# LPC111x/LPC11Cxx/LPC11xxL/LPC11xxXL register map
File version: 6
CPU: CM0 r0p0, little endian, no MPU, no FPU, 2 interrupt priority bits
Registers are 32-bit, read-write, reset 0x0 unless marked. A register's access mark holds for its fields unless they carry their own. Offsets are from the block's base; [hi:lo] are bit positions; 'fields as' and 'values as' point back to an identical list.

## IOCON — I/O Configuration Block
Base 0x40044000
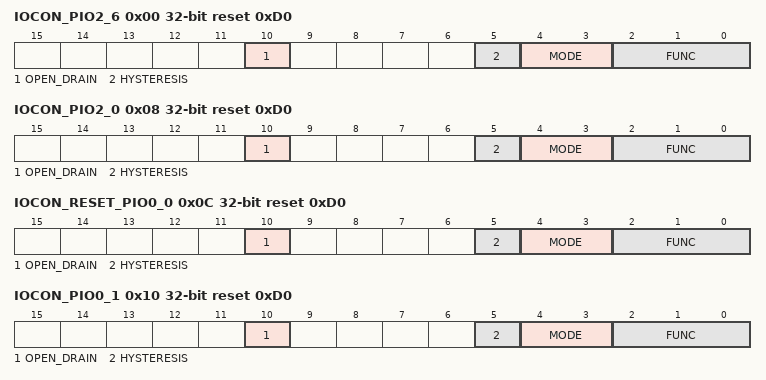
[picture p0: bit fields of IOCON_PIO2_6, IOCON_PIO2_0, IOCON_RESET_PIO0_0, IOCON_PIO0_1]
0x00 IOCON_PIO2_6 reset 0xD0 — I/O configuration for pin PIO2_6/ CT32B0_MAT1
  [10] OPEN_DRAIN — Selects pseudo open-drain mode.
    0=GPIO_OUTPUT (Standard GPIO output); 1=OPEN_DRAIN_OUTPUT
  [5] HYSTERESIS
    0=DISABLE; 1=ENABLE
  [4:3] MODE — Pin function mode (on-chip pull-up/pull-down resistor control).
    0=INACTIVE_NO_PULL_DO (Inactive (no pull-down/pull-up resistor enabled)); 1=PULL_DOWN_RESISTOR_E (Pull-down resistor enabled); 2=PULL_UP_RESISTOR_ENA (Pull-up resistor enabled); 3=REPEATER_MODE_
  [2:0] FUNC — Configure pin function.
    0=PIO2_6 (Pin function PIO2_6); 1=CT32B0_MAT1 (Pin function CT32B0_MAT1)
0x08 IOCON_PIO2_0 reset 0xD0 — I/O configuration for pin PIO2_0/DTR/SSEL1
  [10] OPEN_DRAIN — Selects pseudo open-drain mode.
    0=GPIO_OUTPUT (Standard GPIO output); 1=OPEN_DRAIN_OUTPUT
  [5] HYSTERESIS
    0=DISABLE; 1=ENABLE
  [4:3] MODE — Pin function mode (on-chip pull-up/pull-down resistor control).
    values as IOCON_PIO2_6.MODE
  [2:0] FUNC — Configure pin function.
    0=PIO2_0 (Pin function PIO2_0); 1=DTR (Pin function DTR); 2=SSEL1 (Pin function SSEL1)
0x0C IOCON_RESET_PIO0_0 reset 0xD0 — I/O configuration for pin RESET/PIO0_0
  [10] OPEN_DRAIN — Selects pseudo open-drain mode.
    0=GPIO_OUTPUT (Standard GPIO output); 1=OPEN_DRAIN_OUTPUT
  [5] HYSTERESIS
    0=DISABLE; 1=ENABLE
  [4:3] MODE — Pin function mode (on-chip pull-up/pull-down resistor control).
    values as IOCON_PIO2_6.MODE
  [2:0] FUNC — Configure pin function.
    0=RESET (Pin function RESET); 1=PIO0_0 (Pin function PIO0_0)
0x10 IOCON_PIO0_1 reset 0xD0 — I/O configuration for pin PIO0_1/CLKOUT/CT32B0_MAT2
  [10] OPEN_DRAIN — Selects pseudo open-drain mode.
    0=GPIO_OUTPUT (Standard GPIO output); 1=OPEN_DRAIN_OUTPUT
  [5] HYSTERESIS
    0=DISABLE; 1=ENABLE
  [4:3] MODE — Pin function mode (on-chip pull-up/pull-down resistor control).
    values as IOCON_PIO2_6.MODE
  [2:0] FUNC — Configure pin function.
    0=PIO0_1 (Pin function PIO0_1); 1=CLKOUT (Pin function CLKOUT); 2=CT32B0_MAT2 (Pin function CT32B0_MAT2)
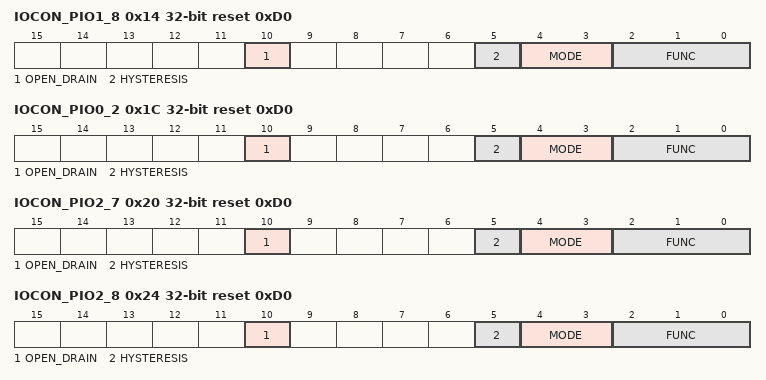
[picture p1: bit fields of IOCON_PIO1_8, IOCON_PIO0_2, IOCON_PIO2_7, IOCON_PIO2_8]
0x14 IOCON_PIO1_8 reset 0xD0 — I/O configuration for pin PIO1_8/CT16B1_CAP0
  [10] OPEN_DRAIN — Selects pseudo open-drain mode.
    0=GPIO_OUTPUT (Standard GPIO output); 1=OPEN_DRAIN_OUTPUT
  [5] HYSTERESIS
    0=DISABLE; 1=ENABLE
  [4:3] MODE — Pin function mode (on-chip pull-up/pull-down resistor control).
    values as IOCON_PIO2_6.MODE
  [2:0] FUNC — Configure pin function.
    0=PIO1_8 (Pin function PIO1_8); 1=CT16B1_CAP0 (Pin function CT16B1_CAP0)
0x18 IOCON_SSEL1_LOC — SSEL1 pin location select register
  [1:0] SSEL1LOC — Selects pin location for SSEL1 function.
    0=PIO2_2 (Function SSEL1 is available for pin PIO2_2); 1=PIO2_4 (Function SSEL1 is available for pin PIO2_4)
0x1C IOCON_PIO0_2 reset 0xD0 — I/O configuration for pin PIO0_2/SSEL0/CT16B0_CAP0
  [10] OPEN_DRAIN — Selects pseudo open-drain mode.
    0=GPIO_OUTPUT (Standard GPIO output); 1=OPEN_DRAIN_OUTPUT
  [5] HYSTERESIS
    0=DISABLE; 1=ENABLE
  [4:3] MODE — Pin function mode (on-chip pull-up/pull-down resistor control).
    values as IOCON_PIO2_6.MODE
  [2:0] FUNC — Configure pin function.
    0=PIO0_2 (Pin function PIO0_2); 1=SSEL0 (Pin function SSEL0); 2=CT16B0_CAP0 (Pin function CT16B0_CAP0)
0x20 IOCON_PIO2_7 reset 0xD0 — I/O configuration for pin PIO2_7/ CT32B0_MAT2/RXD
  [10] OPEN_DRAIN — Selects pseudo open-drain mode.
    0=GPIO_OUTPUT (Standard GPIO output); 1=OPEN_DRAIN_OUTPUT
  [5] HYSTERESIS
    0=DISABLE; 1=ENABLE
  [4:3] MODE — Pin function mode (on-chip pull-up/pull-down resistor control).
    values as IOCON_PIO2_6.MODE
  [2:0] FUNC — Configure pin function.
    0=PIO2_7 (Pin function PIO2_7); 1=CT32B0_MAT2 (Pin function CT32B0_MAT2); 2=RXD (Pin function RXD)
0x24 IOCON_PIO2_8 reset 0xD0 — I/O configuration for pin PIO2_8/ CT32B0_MAT3/TXD
  [10] OPEN_DRAIN — Selects pseudo open-drain mode.
    0=GPIO_OUTPUT (Standard GPIO output); 1=OPEN_DRAIN_OUTPUT
  [5] HYSTERESIS
    0=DISABLE; 1=ENABLE
  [4:3] MODE — Pin function mode (on-chip pull-up/pull-down resistor control).
    values as IOCON_PIO2_6.MODE
  [2:0] FUNC — Configure pin function.
    0=PIO2_8 (Pin function PIO2_8); 1=CT32B0_MAT3 (Pin function CT32B0_MAT3); 2=TXD (Pin function TXD)
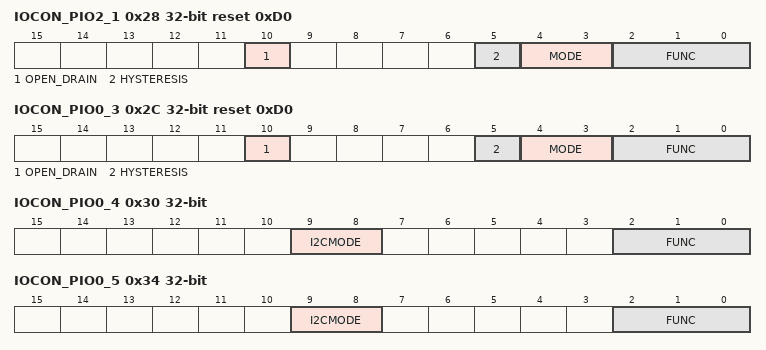
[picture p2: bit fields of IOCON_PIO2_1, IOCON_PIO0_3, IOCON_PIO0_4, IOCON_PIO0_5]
0x28 IOCON_PIO2_1 reset 0xD0 — I/O configuration for pin PIO2_1/DSR/SCK1
  [10] OPEN_DRAIN — Selects pseudo open-drain mode.
    0=GPIO_OUTPUT (Standard GPIO output); 1=OPEN_DRAIN_OUTPUT
  [5] HYSTERESIS
    0=DISABLE; 1=ENABLE
  [4:3] MODE — Pin function mode (on-chip pull-up/pull-down resistor control).
    values as IOCON_PIO2_6.MODE
  [2:0] FUNC — Configure pin function.
    0=PIO2_1 (Pin function PIO2_1); 1=DSR (Pin function DSR); 2=SCK1 (Pin function SCK1)
0x2C IOCON_PIO0_3 reset 0xD0 — I/O configuration for pin PIO0_3
  [10] OPEN_DRAIN — Selects pseudo open-drain mode.
    0=GPIO_OUTPUT (Standard GPIO output); 1=OPEN_DRAIN_OUTPUT
  [5] HYSTERESIS
    0=DISABLE; 1=ENABLE
  [4:3] MODE — Pin function mode (on-chip pull-up/pull-down resistor control).
    values as IOCON_PIO2_6.MODE
  [2:0] FUNC — Configure pin function.
    0=PIO0_3 (Pin function PIO0_3)
0x30 IOCON_PIO0_4 — I/O configuration for pin PIO0_4/SCL
  [9:8] I2CMODE — Selects I2C mode. Select Standard mode (I2CMODE = 00, default) or Standard I/O functionality (I2CMODE = 01) if the pin function is GPIO (FUNC = 000).
    0=STANDARD_MODE_FAST (Standard mode/ Fast-mode I2C); 1=STANDARD_IO_FUNCTION (Standard I/O functionality); 2=FAST_MODE_PLUS_I2C
  [2:0] FUNC — Configure pin function.
    0=PIO0_4 (Pin function PIO0_4 (open-drain pin)); 1=SCL (Pin function SCL (open-drain pin))
0x34 IOCON_PIO0_5 — I/O configuration for pin PIO0_5/SDA
  [9:8] I2CMODE — Selects I2C mode. Select Standard mode (I2CMODE = 00, default) or Standard I/O functionality (I2CMODE = 01) if the pin function is GPIO (FUNC = 000).
    values as IOCON_PIO0_4.I2CMODE
  [2:0] FUNC — Configure pin function.
    0=PIO0_5 (Pin function PIO0_5 (open-drain pin)); 1=SDA (Pin function SDA (open-drain pin))
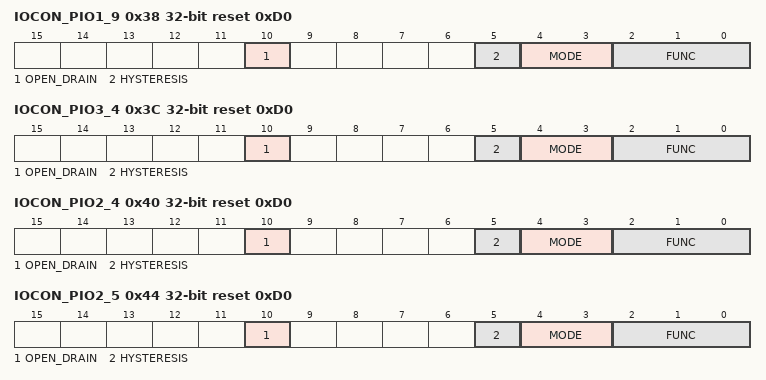
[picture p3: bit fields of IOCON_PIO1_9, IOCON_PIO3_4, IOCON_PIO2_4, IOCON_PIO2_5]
0x38 IOCON_PIO1_9 reset 0xD0 — I/O configuration for pin PIO1_9/CT16B1_MAT0/ MOSI1
  [10] OPEN_DRAIN — Selects pseudo open-drain mode.
    0=GPIO_OUTPUT (Standard GPIO output); 1=OPEN_DRAIN_OUTPUT
  [5] HYSTERESIS
    0=DISABLE; 1=ENABLE
  [4:3] MODE — Pin function mode (on-chip pull-up/pull-down resistor control).
    values as IOCON_PIO2_6.MODE
  [2:0] FUNC — Configure pin function.
    0=PIO1_9 (Pin function PIO1_9); 1=CT16B1_MAT0 (Pin function CT16B1_MAT0); 2=MOSI1 (Pin function MOSI1)
0x3C IOCON_PIO3_4 reset 0xD0 — I/O configuration for pin PIO3_4/ CT16B0_CAP1/RXD
  [10] OPEN_DRAIN — Selects pseudo open-drain mode.
    0=GPIO_OUTPUT (Standard GPIO output); 1=OPEN_DRAIN_OUTPUT
  [5] HYSTERESIS
    0=DISABLE; 1=ENABLE
  [4:3] MODE — Pin function mode (on-chip pull-up/pull-down resistor control).
    values as IOCON_PIO2_6.MODE
  [2:0] FUNC — Configure pin function.
    0=PIO3_4 (Pin function PIO3_4); 1=CT16B0_CAP1 (Pin function CT16B0_CAP1); 2=RXD (Pin function RXD)
0x40 IOCON_PIO2_4 reset 0xD0 — I/O configuration for pin PIO2_4/ CT16B1_MAT1/ SSEL1
  [10] OPEN_DRAIN — Selects pseudo open-drain mode.
    0=GPIO_OUTPUT (Standard GPIO output); 1=OPEN_DRAIN_OUTPUT
  [5] HYSTERESIS
    0=DISABLE; 1=ENABLE
  [4:3] MODE — Pin function mode (on-chip pull-up/pull-down resistor control).
    values as IOCON_PIO2_6.MODE
  [2:0] FUNC — Configure pin function.
    0=PIO2_4 (Pin function PIO2_4); 1=CT16B1_MAT1 (Pin function CT16B1_MAT1); 2=SSEL1 (Pin function SSEL1)
0x44 IOCON_PIO2_5 reset 0xD0 — I/O configuration for pin PIO2_5/ CT32B0_MAT0
  [10] OPEN_DRAIN — Selects pseudo open-drain mode.
    0=GPIO_OUTPUT (Standard GPIO output); 1=OPEN_DRAIN_OUTPUT
  [5] HYSTERESIS
    0=DISABLE; 1=ENABLE
  [4:3] MODE — Pin function mode (on-chip pull-up/pull-down resistor control).
    values as IOCON_PIO2_6.MODE
  [2:0] FUNC — Configure pin function.
    0=PIO2_5 (Pin function PIO2_5); 1=CT32B0_MAT0 (Pin function CT32B0_MAT0)
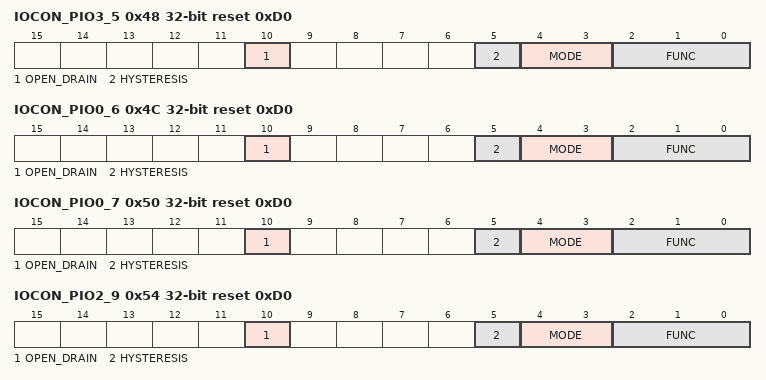
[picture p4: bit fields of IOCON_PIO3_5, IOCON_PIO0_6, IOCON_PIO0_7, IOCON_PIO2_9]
0x48 IOCON_PIO3_5 reset 0xD0 — I/O configuration for pin PIO3_5/ CT16B1_CAP1/TXD
  [10] OPEN_DRAIN — Selects pseudo open-drain mode.
    0=GPIO_OUTPUT (Standard GPIO output); 1=OPEN_DRAIN_OUTPUT
  [5] HYSTERESIS
    0=DISABLE; 1=ENABLE
  [4:3] MODE — Pin function mode (on-chip pull-up/pull-down resistor control).
    values as IOCON_PIO2_6.MODE
  [2:0] FUNC — Configure pin function.
    0=PIO3_5 (Pin function PIO3_5); 1=CT16B1_CAP1 (Pin function CT16B1_CAP1); 2=TXD (Pin function TXD)
0x4C IOCON_PIO0_6 reset 0xD0 — I/O configuration for pin PIO0_6/SCK0
  [10] OPEN_DRAIN — Selects pseudo open-drain mode.
    0=GPIO_OUTPUT (Standard GPIO output); 1=OPEN_DRAIN_OUTPUT
  [5] HYSTERESIS
    0=DISABLE; 1=ENABLE
  [4:3] MODE — Pin function mode (on-chip pull-up/pull-down resistor control).
    values as IOCON_PIO2_6.MODE
  [2:0] FUNC — Configure pin function.
    0=PIO0_6 (Pin function PIO0_6); 2=SCK0 (Pin function SCK0 (available depending on SCK location register))
0x50 IOCON_PIO0_7 reset 0xD0 — I/O configuration for pin PIO0_7/CTS
  [10] OPEN_DRAIN — Selects pseudo open-drain mode.
    0=GPIO_OUTPUT (Standard GPIO output); 1=OPEN_DRAIN_OUTPUT
  [5] HYSTERESIS
    0=DISABLE; 1=ENABLE
  [4:3] MODE — Pin function mode (on-chip pull-up/pull-down resistor control).
    values as IOCON_PIO2_6.MODE
  [2:0] FUNC — Configure pin function.
    0=PIO0_7 (Pin function PIO0_7); 1=CTS (Pin function CTS)
0x54 IOCON_PIO2_9 reset 0xD0 — I/O configuration for pin PIO2_9/ CT32B0_CAP0
  [10] OPEN_DRAIN — Selects pseudo open-drain mode.
    0=GPIO_OUTPUT (Standard GPIO output); 1=OPEN_DRAIN_OUTPUT
  [5] HYSTERESIS
    0=DISABLE; 1=ENABLE
  [4:3] MODE — Pin function mode (on-chip pull-up/pull-down resistor control).
    values as IOCON_PIO2_6.MODE
  [2:0] FUNC — Configure pin function.
    0=PIO2_9 (Pin function PIO2_9); 1=CT32B0_CAP0 (Pin function CT32B0_CAP0)
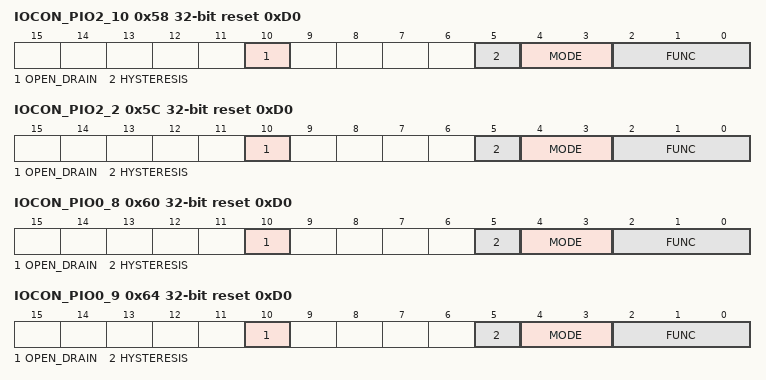
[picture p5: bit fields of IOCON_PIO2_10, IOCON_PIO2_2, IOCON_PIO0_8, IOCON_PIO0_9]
0x58 IOCON_PIO2_10 reset 0xD0 — I/O configuration for pin PIO2_10
  [10] OPEN_DRAIN — Selects pseudo open-drain mode.
    0=GPIO_OUTPUT (Standard GPIO output); 1=OPEN_DRAIN_OUTPUT
  [5] HYSTERESIS
    0=DISABLE; 1=ENABLE
  [4:3] MODE — Pin function mode (on-chip pull-up/pull-down resistor control).
    values as IOCON_PIO2_6.MODE
  [2:0] FUNC — Configure pin function.
    0=PIO2_10 (Pin function PIO2_10)
0x5C IOCON_PIO2_2 reset 0xD0 — I/O configuration for pin PIO2_2/DCD/MISO1
  [10] OPEN_DRAIN — Selects pseudo open-drain mode.
    0=GPIO_OUTPUT (Standard GPIO output); 1=OPEN_DRAIN_OUTPUT
  [5] HYSTERESIS
    0=DISABLE; 1=ENABLE
  [4:3] MODE — Pin function mode (on-chip pull-up/pull-down resistor control).
    values as IOCON_PIO2_6.MODE
  [2:0] FUNC — Configure pin function.
    0=PIO2_2 (Pin function PIO2_2); 1=DCD (Pin function DCD); 2=MISO1 (Pin function MISO1)
0x60 IOCON_PIO0_8 reset 0xD0 — I/O configuration for pin PIO0_8/MISO0/CT16B0_MAT0
  [10] OPEN_DRAIN — Selects pseudo open-drain mode.
    0=GPIO_OUTPUT (Standard GPIO output); 1=OPEN_DRAIN_OUTPUT
  [5] HYSTERESIS
    0=DISABLE; 1=ENABLE
  [4:3] MODE — Pin function mode (on-chip pull-up/pull-down resistor control).
    values as IOCON_PIO2_6.MODE
  [2:0] FUNC — Configure pin function.
    0=PIO0_8 (Pin function PIO0_8); 1=MISO0 (Pin function MISO0); 2=CT16B0_MAT0 (Pin function CT16B0_MAT0)
0x64 IOCON_PIO0_9 reset 0xD0 — I/O configuration for pin PIO0_9/MOSI0/CT16B0_MAT1
  [10] OPEN_DRAIN — Selects pseudo open-drain mode.
    0=GPIO_OUTPUT (Standard GPIO output); 1=OPEN_DRAIN_OUTPUT
  [5] HYSTERESIS
    0=DISABLE; 1=ENABLE
  [4:3] MODE — Pin function mode (on-chip pull-up/pull-down resistor control).
    values as IOCON_PIO2_6.MODE
  [2:0] FUNC — Configure pin function.
    0=PIO0_9 (Pin function PIO0_9); 1=MOSI0 (Pin function MOSI0); 2=CT16B0_MAT1 (Pin function CT16B0_MAT1)
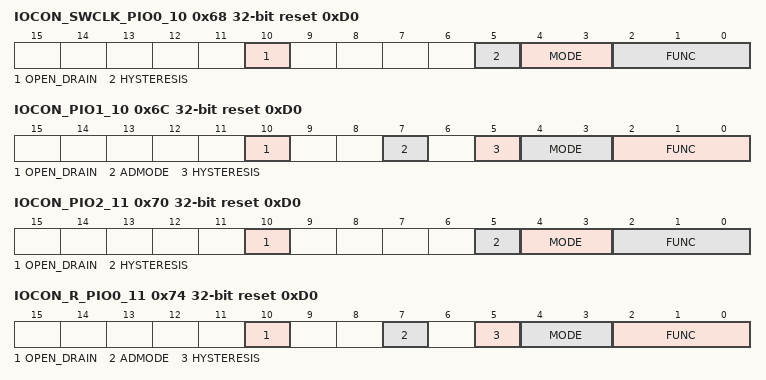
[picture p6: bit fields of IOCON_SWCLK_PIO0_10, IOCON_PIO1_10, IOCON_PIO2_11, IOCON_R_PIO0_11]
0x68 IOCON_SWCLK_PIO0_10 reset 0xD0 — I/O configuration for pin SWCLK/PIO0_10/ SCK0/CT16B0_MAT2
  [10] OPEN_DRAIN — Selects pseudo open-drain mode.
    0=GPIO_OUTPUT (Standard GPIO output); 1=OPEN_DRAIN_OUTPUT
  [5] HYSTERESIS
    0=DISABLE; 1=ENABLE
  [4:3] MODE — Pin function mode (on-chip pull-up/pull-down resistor control).
    values as IOCON_PIO2_6.MODE
  [2:0] FUNC — Configure pin function.
    0=SWCLK (Pin function SWCLK); 1=PIO0_10 (Pin function PIO0_10); 2=SCK0 (Pin function SCK0 (available depending on SCK location register)); 3=CT16B0_MAT2 (Pin function CT16B0_MAT2)
0x6C IOCON_PIO1_10 reset 0xD0 — I/O configuration for pin PIO1_10/AD6/CT16B1_MAT1/ MISO1
  [10] OPEN_DRAIN — Selects pseudo open-drain mode.
    0=GPIO_OUTPUT (Standard GPIO output); 1=OPEN_DRAIN_OUTPUT
  [7] ADMODE — Selects Analog/Digital mode.
    0=ANALOG_INPUT_MODE; 1=DIGITAL_FUNCTIONAL_M (Digital functional mode)
  [5] HYSTERESIS
    0=DISABLE; 1=ENABLE
  [4:3] MODE — Pin function mode (on-chip pull-up/pull-down resistor control).
    values as IOCON_PIO2_6.MODE
  [2:0] FUNC — Configure pin function.
    0=PIO1_10 (Pin function PIO1_10); 1=AD6 (Pin function AD6); 2=CT16B1_MAT1 (Pin function CT16B1_MAT1); 3=MISO1 (Pin function MISO1)
0x70 IOCON_PIO2_11 reset 0xD0 — I/O configuration for pin PIO2_11/SCK0/ CT32B0_CAP1
  [10] OPEN_DRAIN — Selects pseudo open-drain mode.
    0=GPIO_OUTPUT (Standard GPIO output); 1=OPEN_DRAIN_OUTPUT
  [5] HYSTERESIS
    0=DISABLE; 1=ENABLE
  [4:3] MODE — Pin function mode (on-chip pull-up/pull-down resistor control).
    values as IOCON_PIO2_6.MODE
  [2:0] FUNC — Configure pin function.
    0=PIO2_11 (Pin function PIO2_11); 1=SELECT_FUNCTION_SCK0 (Pin function SCK0 (only if pin PIO2_11/SCK0 selected in Table 147)); 2=CT32B0_CAP1 (Pin function CT32B0_CAP1)
0x74 IOCON_R_PIO0_11 reset 0xD0 — I/O configuration for pin R/PIO0_11/AD0/CT32B0_MAT3
  [10] OPEN_DRAIN — Selects pseudo open-drain mode.
    0=GPIO_OUTPUT (Standard GPIO output); 1=OPEN_DRAIN_OUTPUT
  [7] ADMODE — Selects Analog/Digital mode.
    values as IOCON_PIO1_10.ADMODE
  [5] HYSTERESIS
    0=DISABLE; 1=ENABLE
  [4:3] MODE — Pin function mode (on-chip pull-up/pull-down resistor control).
    values as IOCON_PIO2_6.MODE
  [2:0] FUNC — Configure pin function.
    1=PIO0_11 (Pin function PIO0_11); 2=AD0 (Pin function AD0); 3=CT32B0_MAT3 (Pin function CT32B0_MAT3)
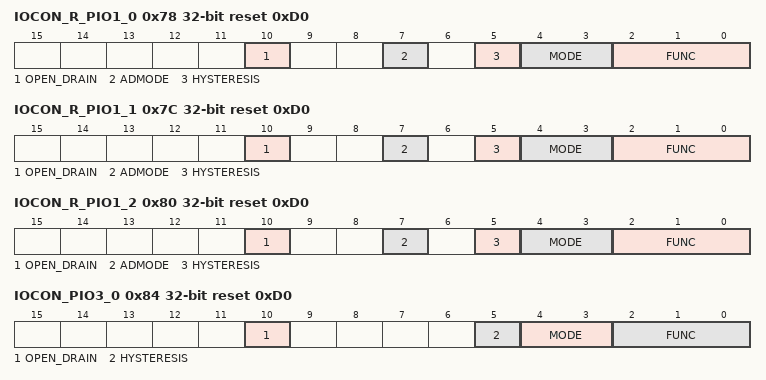
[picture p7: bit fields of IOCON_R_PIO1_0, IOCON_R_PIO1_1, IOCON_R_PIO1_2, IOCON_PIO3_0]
0x78 IOCON_R_PIO1_0 reset 0xD0 — I/O configuration for pin R/PIO1_0/AD1/CT32B1_CAP0
  [10] OPEN_DRAIN — Selects pseudo open-drain mode.
    0=GPIO_OUTPUT (Standard GPIO output); 1=OPEN_DRAIN_OUTPUT
  [7] ADMODE — Selects Analog/Digital mode.
    values as IOCON_PIO1_10.ADMODE
  [5] HYSTERESIS
    0=DISABLE; 1=ENABLE
  [4:3] MODE — Pin function mode (on-chip pull-up/pull-down resistor control).
    values as IOCON_PIO2_6.MODE
  [2:0] FUNC — Configure pin function.
    1=PIO1_0 (Pin function PIO1_0); 2=AD1 (Pin function AD1); 3=CT32B1_CAP0 (Pin function CT32B1_CAP0)
0x7C IOCON_R_PIO1_1 reset 0xD0 — I/O configuration for pin R/PIO1_1/AD2/CT32B1_MAT0
  [10] OPEN_DRAIN — Selects pseudo open-drain mode.
    0=GPIO_OUTPUT (Standard GPIO output); 1=OPEN_DRAIN_OUTPUT
  [7] ADMODE — Selects Analog/Digital mode.
    values as IOCON_PIO1_10.ADMODE
  [5] HYSTERESIS
    0=DISABLE; 1=ENABLE
  [4:3] MODE — Pin function mode (on-chip pull-up/pull-down resistor control).
    values as IOCON_PIO2_6.MODE
  [2:0] FUNC — Configure pin function.
    1=PIO1_1 (Pin function PIO1_1); 2=AD2 (Pin function AD2); 3=CT32B1_MAT0 (Pin function CT32B1_MAT0)
0x80 IOCON_R_PIO1_2 reset 0xD0 — I/O configuration for pin R/PIO1_2/AD3/CT32B1_MAT1
  [10] OPEN_DRAIN — Selects pseudo open-drain mode.
    0=GPIO_OUTPUT (Standard GPIO output); 1=OPEN_DRAIN_OUTPUT
  [7] ADMODE — Selects Analog/Digital mode.
    values as IOCON_PIO1_10.ADMODE
  [5] HYSTERESIS
    0=DISABLE; 1=ENABLE
  [4:3] MODE — Pin function mode (on-chip pull-up/pull-down resistor control).
    values as IOCON_PIO2_6.MODE
  [2:0] FUNC — Configure pin function.
    1=PIO1_2 (Pin function PIO1_2); 2=AD3 (Pin function AD3); 3=CT32B1_MAT1 (Pin function CT32B1_MAT1)
0x84 IOCON_PIO3_0 reset 0xD0 — I/O configuration for pin PIO3_0/DTR/CT16B0_MAT0/TXD
  [10] OPEN_DRAIN — Selects pseudo open-drain mode.
    0=GPIO_OUTPUT (Standard GPIO output); 1=OPEN_DRAIN_OUTPUT
  [5] HYSTERESIS
    0=DISABLE; 1=ENABLE
  [4:3] MODE — Pin function mode (on-chip pull-up/pull-down resistor control).
    values as IOCON_PIO2_6.MODE
  [2:0] FUNC — Configure pin function.
    0=PIO3_0 (Pin function PIO3_0); 1=DTR (Pin function DTR); 2=CT16B0_MAT0 (Pin function CT16B0_MAT0); 3=TXD (Pin function TXD)
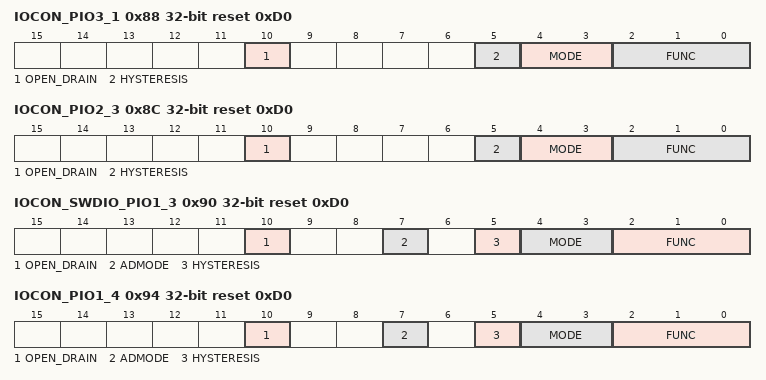
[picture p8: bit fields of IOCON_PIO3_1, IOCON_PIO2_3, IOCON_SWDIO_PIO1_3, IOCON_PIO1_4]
0x88 IOCON_PIO3_1 reset 0xD0 — I/O configuration for pin PIO3_1/DSR/CT16B0_MAT1/RXD
  [10] OPEN_DRAIN — Selects pseudo open-drain mode.
    0=GPIO_OUTPUT (Standard GPIO output); 1=OPEN_DRAIN_OUTPUT
  [5] HYSTERESIS
    0=DISABLE; 1=ENABLE
  [4:3] MODE — Pin function mode (on-chip pull-up/pull-down resistor control).
    values as IOCON_PIO2_6.MODE
  [2:0] FUNC — Configure pin function.
    0=PIO3_1 (Pin function PIO3_1); 1=DSR (Pin function DSR); 2=CT16B0_MAT1 (Pin function CT16B0_MAT1); 3=RXD (Pin function RXD)
0x8C IOCON_PIO2_3 reset 0xD0 — I/O configuration for pin PIO2_3/RI/MOSI1
  [10] OPEN_DRAIN — Selects pseudo open-drain mode.
    0=GPIO_OUTPUT (Standard GPIO output); 1=OPEN_DRAIN_OUTPUT
  [5] HYSTERESIS
    0=DISABLE; 1=ENABLE
  [4:3] MODE — Pin function mode (on-chip pull-up/pull-down resistor control).
    values as IOCON_PIO2_6.MODE
  [2:0] FUNC — Configure pin function.
    0=PIO2_3 (Pin function PIO2_3); 1=RI (Pin function RI); 2=MOSI1 (Pin function MOSI1)
0x90 IOCON_SWDIO_PIO1_3 reset 0xD0 — I/O configuration for pin SWDIO/PIO1_3/AD4/CT32B1_MAT2
  [10] OPEN_DRAIN — Selects pseudo open-drain mode.
    0=GPIO_OUTPUT (Standard GPIO output); 1=OPEN_DRAIN_OUTPUT
  [7] ADMODE — Selects Analog/Digital mode.
    values as IOCON_PIO1_10.ADMODE
  [5] HYSTERESIS
    0=DISABLE; 1=ENABLE
  [4:3] MODE — Pin function mode (on-chip pull-up/pull-down resistor control).
    values as IOCON_PIO2_6.MODE
  [2:0] FUNC — Configure pin function.
    0=SWDIO (Pin function SWDIO); 1=PIO1_3 (Pin function PIO1_3); 2=AD4 (Pin function AD4); 3=CT32B1_MAT2 (Pin function CT32B1_MAT2)
0x94 IOCON_PIO1_4 reset 0xD0 — I/O configuration for pin PIO1_4/AD5/CT32B1_MAT3
  [10] OPEN_DRAIN — Selects pseudo open-drain mode.
    0=GPIO_OUTPUT (Standard GPIO output); 1=OPEN_DRAIN_OUTPUT
  [7] ADMODE — Selects Analog/Digital mode.
    values as IOCON_PIO1_10.ADMODE
  [5] HYSTERESIS
    0=DISABLE; 1=ENABLE
  [4:3] MODE — Pin function mode (on-chip pull-up/pull-down resistor control).
    values as IOCON_PIO2_6.MODE
  [2:0] FUNC — Selects pin function. This pin functions as WAKEUP pin if the LPC111x/LPC11Cxx is in Deep power-down mode regardless of the value of FUNC. All other values are reserved.
    0=PIO1_4 (Pin function PIO1_4); 1=AD5 (Pin function AD5); 2=CT32B1_MAT3 (Pin function CT32B1_MAT3)
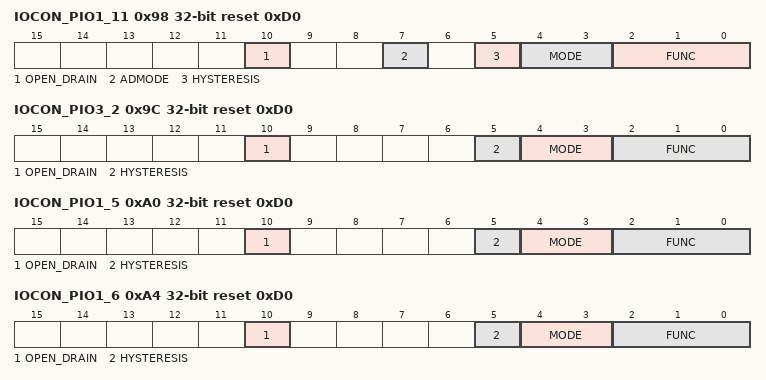
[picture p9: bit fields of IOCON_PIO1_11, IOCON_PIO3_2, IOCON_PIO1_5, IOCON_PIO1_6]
0x98 IOCON_PIO1_11 reset 0xD0 — I/O configuration for pin PIO1_11/AD7/CT32B1_CAP1
  [10] OPEN_DRAIN — Selects pseudo open-drain mode.
    0=GPIO_OUTPUT (Standard GPIO output); 1=OPEN_DRAIN_OUTPUT
  [7] ADMODE — Selects Analog/Digital mode.
    values as IOCON_PIO1_10.ADMODE
  [5] HYSTERESIS
    0=DISABLE; 1=ENABLE
  [4:3] MODE — Pin function mode (on-chip pull-up/pull-down resistor control).
    values as IOCON_PIO2_6.MODE
  [2:0] FUNC — Configure pin function.
    0=PIO1_11 (Pin function PIO1_11); 1=AD7 (Pin function AD7); 2=CT32B1_CAP1 (Pin function CT32B1_CAP1)
0x9C IOCON_PIO3_2 reset 0xD0 — I/O configuration for pin PIO3_2/DCD/ CT16B0_MAT2/SCK1
  [10] OPEN_DRAIN — Selects pseudo open-drain mode.
    0=GPIO_OUTPUT (Standard GPIO output); 1=OPEN_DRAIN_OUTPUT
  [5] HYSTERESIS
    0=DISABLE; 1=ENABLE
  [4:3] MODE — Pin function mode (on-chip pull-up/pull-down resistor control).
    values as IOCON_PIO2_6.MODE
  [2:0] FUNC — Configure pin function.
    0=PIO3_2 (Pin function PIO3_2); 1=DCD (Pin function DCD); 2=CT16B0_MAT2 (Pin function CT16B0_MAT2); 3=SCK1 (Pin function SCK1)
0xA0 IOCON_PIO1_5 reset 0xD0 — I/O configuration for pin PIO1_5/RTS/CT32B0_CAP0
  [10] OPEN_DRAIN — Selects pseudo open-drain mode.
    0=GPIO_OUTPUT (Standard GPIO output); 1=OPEN_DRAIN_OUTPUT
  [5] HYSTERESIS
    0=DISABLE; 1=ENABLE
  [4:3] MODE — Pin function mode (on-chip pull-up/pull-down resistor control).
    values as IOCON_PIO2_6.MODE
  [2:0] FUNC — Configure pin function.
    0=PIO1_5 (Pin function PIO1_5); 1=RTS (Pin function RTS); 2=CT32B0_CAP0 (Pin function CT32B0_CAP0)
0xA4 IOCON_PIO1_6 reset 0xD0 — I/O configuration for pin PIO1_6/RXD/CT32B0_MAT0
  [10] OPEN_DRAIN — Selects pseudo open-drain mode.
    0=GPIO_OUTPUT (Standard GPIO output); 1=OPEN_DRAIN_OUTPUT
  [5] HYSTERESIS
    0=DISABLE; 1=ENABLE
  [4:3] MODE — Pin function mode (on-chip pull-up/pull-down resistor control).
    values as IOCON_PIO2_6.MODE
  [2:0] FUNC — Configure pin function.
    0=PIO1_6 (Pin function PIO1_6); 1=RXD (Pin function RXD); 2=CT32B0_MAT0 (Pin function CT32B0_MAT0)
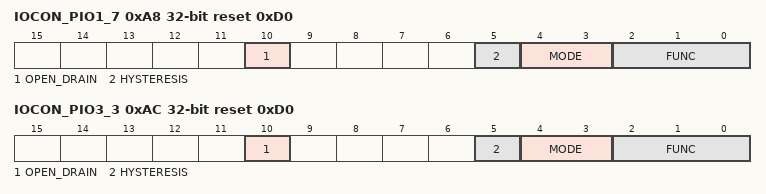
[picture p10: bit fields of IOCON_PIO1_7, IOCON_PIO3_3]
0xA8 IOCON_PIO1_7 reset 0xD0 — I/O configuration for pin PIO1_7/TXD/CT32B0_MAT1
  [10] OPEN_DRAIN — Selects pseudo open-drain mode.
    0=GPIO_OUTPUT (Standard GPIO output); 1=OPEN_DRAIN_OUTPUT
  [5] HYSTERESIS
    0=DISABLE; 1=ENABLE
  [4:3] MODE — Pin function mode (on-chip pull-up/pull-down resistor control).
    values as IOCON_PIO2_6.MODE
  [2:0] FUNC — Configure pin function.
    0=PIO1_7 (Pin function PIO1_7); 1=TXD (Pin function TXD); 2=CT32B0_MAT1 (Pin function CT32B0_MAT1)
0xAC IOCON_PIO3_3 reset 0xD0 — I/O configuration for pin PIO3_3/RI/ CT16B0_CAP0
  [10] OPEN_DRAIN — Selects pseudo open-drain mode.
    0=GPIO_OUTPUT (Standard GPIO output); 1=OPEN_DRAIN_OUTPUT
  [5] HYSTERESIS
    0=DISABLE; 1=ENABLE
  [4:3] MODE — Pin function mode (on-chip pull-up/pull-down resistor control).
    values as IOCON_PIO2_6.MODE
  [2:0] FUNC — Configure pin function.
    0=PIO3_3 (Pin function PIO3_3); 1=RI (Pin function RI); 2=CT16B0_CAP0 (Pin function CT16B0_CAP0)
0xB0 IOCON_SCK0_LOC — SCK0 pin location select register
  [1:0] SCKLOC — Selects pin location for SCK0 function.
    0=PIO0_10 (Function SCK0 is available for pin PIO0_10); 1=PIO2_11 (Function SCK0 is available for pin PIO2_11); 2=PIO0_6 (Function SCK0 is available for pin PIO0_6)
0xB4 IOCON_DSR_LOC — DSR pin location select register
  [1:0] DSRLOC — Selects pin location for DSR function.
    0=PIO2_1 (Function DSR is available for pin PIO2_1); 1=PIO3_1 (Function DSR is available for pin PIO3_1)
0xB8 IOCON_DCD_LOC — DCD pin location select register
  [1:0] DCDLOC — Selects pin location for DCD function.
    0=PIO2_2 (Function DCD is available for pin PIO2_2); 1=PIO3_2 (Function DCD is available for pin PIO3_2)
0xBC IOCON_RI_LOC — RI pin location select register
  [1:0] RILOC — Selects pin location for RI function.
    0=PIO2_3 (Function RI is available for pin PIO2_3); 1=PIO3_3 (Function RI is available for pin PIO3_3)
0xC0 IOCON_CT16B0_CAP0_LOC — CT16B0_CAP0 pin location select register
  [1:0] CT16B0_CAP0LOC — Selects pin location for CT16B0_CAP0 function.
    0=PIO0_2 (Function CT16B0_CAP0 is available for pin PIO0_2); 1=PIO3_3 (Function CT16B0_CAP0 is available for pin PIO3_3)
0xC4 IOCON_SCK1_LOC — SCK1 pin location select register
  [1:0] SCK1LOC — Selects pin location for SCK1 function.
    0=PIO2_1 (Function SCK1 is available for pin PIO2_1); 1=PIO3_2 (Function SCK1 is available for pin PIO3_2)
0xC8 IOCON_MISO1_LOC — MISO1 pin location select register
  [1:0] MISO1LOC — Selects pin location for the MISO1 function.
    0=PIO2_2 (Function MISO1 is available for pin PIO2_2); 1=PIO1_10 (Function MISO1 is available for pin PIO1_10)
0xCC IOCON_MOSI1_LOC — MOSI1 pin location select register
  [1:0] MOSI1LOC — Selects pin location for the MOSI1 function.
    0=PIO2_3 (Function MOSI1 is available for pin PIO2_3); 1=PIO1_9 (Function MOSI1 is available for pin PIO1_9)
0xD0 IOCON_CT32B0_CAP0_LOC — CT32B0_CAP0 pin location select register
  [1:0] CT32B0_CAP0LOC — Selects pin location for the CT32B0_CAP0 function.
    0=PIO1_5 (Function CT32B0_CAP0 is available for pin PIO1_5); 1=PIO2_9 (Function CT32B0_CAP0 is available for pin PIO2_9)
0xD4 IOCON_RXD_LOC — RXD pin location select register
  [1:0] RXDLOC — Selects pin location for the RXD function.
    0=PIO1_6 (Function RXD is available for pin PIO1_6); 1=PIO2_7 (Function RXD is available for pin PIO2_7); 2=PIO3_1 (Function RXD is available for pin PIO3_1); 3=PIO3_4 (Function RXD is available for pin PIO3_4)
